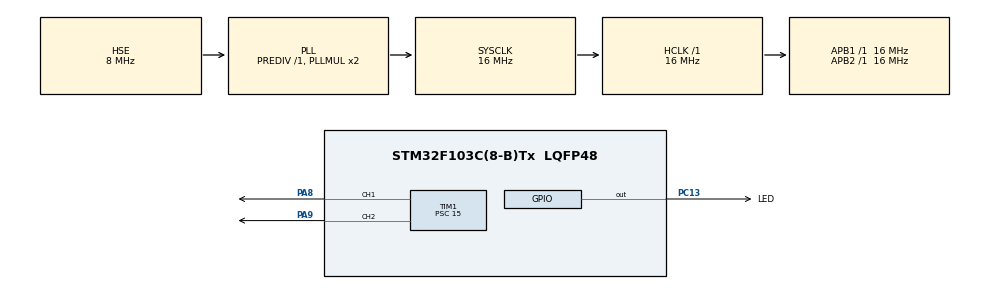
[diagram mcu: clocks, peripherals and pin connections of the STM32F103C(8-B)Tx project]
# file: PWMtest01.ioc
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Mcu.Family=STM32F1
Mcu.Name=STM32F103C(8-B)Tx
Mcu.Package=LQFP48
NVIC.PriorityGroup=NVIC_PRIORITYGROUP_4
PA13.Mode=JTAG_4_pins
PA13.Signal=SYS_JTMS-SWDIO
PA14.Mode=JTAG_4_pins
PA14.Signal=SYS_JTCK-SWCLK
PA15.Mode=JTAG_4_pins
PA15.Signal=SYS_JTDI
PA8.Signal=S_TIM1_CH1
PA9.Signal=S_TIM1_CH2
PB3.Mode=JTAG_4_pins
PB3.Signal=SYS_JTDO-TRACESWO
PC13-TAMPER-RTC.GPIO_Label=LED
PC13-TAMPER-RTC.PinState=GPIO_PIN_SET
PC13-TAMPER-RTC.Signal=GPIO_Output
PD0-OSC_IN.Mode=HSE-External-Oscillator
PD0-OSC_IN.Signal=RCC_OSC_IN
PD1-OSC_OUT.Mode=HSE-External-Oscillator
PD1-OSC_OUT.Signal=RCC_OSC_OUT
ProjectManager.HeapSize=0x200
ProjectManager.StackSize=0x400
ProjectManager.TargetToolchain=MDK-ARM V5.27
RCC.AHBFreq_Value=16000000
RCC.APB1Freq_Value=16000000
RCC.APB1TimFreq_Value=16000000
RCC.APB2Freq_Value=16000000
RCC.APB2TimFreq_Value=16000000
RCC.HCLKFreq_Value=16000000
RCC.PLLSourceVirtual=RCC_PLLSOURCE_HSE
RCC.SYSCLKFreq_VALUE=16000000
RCC.SYSCLKSource=RCC_SYSCLKSOURCE_PLLCLK
RCC.USBFreq_Value=16000000
SH.S_TIM1_CH1.0=TIM1_CH1,PWM Generation1 CH1
SH.S_TIM1_CH2.0=TIM1_CH2,PWM Generation2 CH2
TIM1.AutoReloadPreload=TIM_AUTORELOAD_PRELOAD_ENABLE
TIM1.Channel-PWM\ Generation1\ CH1=TIM_CHANNEL_1
TIM1.Channel-PWM\ Generation2\ CH2=TIM_CHANNEL_2
TIM1.OCMode_PWM-PWM\ Generation2\ CH2=TIM_OCMODE_PWM1
TIM1.Period=20000
TIM1.Prescaler=15
TIM1.Pulse-PWM\ Generation1\ CH1=50
TIM1.Pulse-PWM\ Generation2\ CH2=50
VP_TIM1_VS_ClockSourceINT.Mode=Internal
board=custom

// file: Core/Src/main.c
/* USER CODE BEGIN Header */
/**
  ******************************************************************************
  * @file           : main.c
  * @brief          : Main program body
  ******************************************************************************
  * @attention
  *
  * <h2><center>&copy; Copyright (c) 2021 STMicroelectronics.
  * All rights reserved.</center></h2>
  *
  * This software component is licensed by ST under BSD 3-Clause license,
  * the "License"; You may not use this file except in compliance with the
  * License. You may obtain a copy of the License at:
  *                        opensource.org/licenses/BSD-3-Clause
  *
  ******************************************************************************
  */
/* USER CODE END Header */
#include "main.h"
#include "tim.h"
#include "gpio.h"

/* USER CODE BEGIN Includes */
int j=0,k=0;
/* USER CODE END Includes */

void SystemClock_Config(void);

int main(void)
{

  /* MCU Configuration--------------------------------------------------------*/

  /* Reset of all peripherals, Initializes the Flash interface and the Systick. */
  HAL_Init();

  /* Configure the system clock */
  SystemClock_Config();

  /* Initialize all configured peripherals */
  MX_GPIO_Init();
  MX_TIM1_Init();
  /* USER CODE BEGIN 2 */

  HAL_TIM_PWM_Start(&htim1,TIM_CHANNEL_1);
	HAL_TIM_PWM_Start(&htim1,TIM_CHANNEL_2);
  /* USER CODE END 2 */

  /* Infinite loop */
  /* USER CODE BEGIN WHILE */
  while (1)
  {
		HAL_GPIO_TogglePin(LED_GPIO_Port,LED_Pin);
		HAL_Delay(10);
     __HAL_TIM_SetCompare(&htim1, TIM_CHANNEL_1, j);
		     __HAL_TIM_SetCompare(&htim1, TIM_CHANNEL_2, k);
		j+=10;
		k+=10;
		if(j>19900)j=0;
		if(k>19900)k=0;
    /* USER CODE END WHILE */

  }
}

void SystemClock_Config(void)
{
  RCC_OscInitTypeDef RCC_OscInitStruct = {0};
  RCC_ClkInitTypeDef RCC_ClkInitStruct = {0};

  /** Initializes the RCC Oscillators according to the specified parameters
  * in the RCC_OscInitTypeDef structure.
  */
  RCC_OscInitStruct.OscillatorType = RCC_OSCILLATORTYPE_HSE;
  RCC_OscInitStruct.HSEState = RCC_HSE_ON;
  RCC_OscInitStruct.HSEPredivValue = RCC_HSE_PREDIV_DIV1;
  RCC_OscInitStruct.HSIState = RCC_HSI_ON;
  RCC_OscInitStruct.PLL.PLLState = RCC_PLL_ON;
  RCC_OscInitStruct.PLL.PLLSource = RCC_PLLSOURCE_HSE;
  RCC_OscInitStruct.PLL.PLLMUL = RCC_PLL_MUL2;
  if (HAL_RCC_OscConfig(&RCC_OscInitStruct) != HAL_OK)
  {
    Error_Handler();
  }
  /** Initializes the CPU, AHB and APB buses clocks
  */
  RCC_ClkInitStruct.ClockType = RCC_CLOCKTYPE_HCLK|RCC_CLOCKTYPE_SYSCLK
                              |RCC_CLOCKTYPE_PCLK1|RCC_CLOCKTYPE_PCLK2;
  RCC_ClkInitStruct.SYSCLKSource = RCC_SYSCLKSOURCE_PLLCLK;
  RCC_ClkInitStruct.AHBCLKDivider = RCC_SYSCLK_DIV1;
  RCC_ClkInitStruct.APB1CLKDivider = RCC_HCLK_DIV1;
  RCC_ClkInitStruct.APB2CLKDivider = RCC_HCLK_DIV1;

  if (HAL_RCC_ClockConfig(&RCC_ClkInitStruct, FLASH_LATENCY_0) != HAL_OK)
  {
    Error_Handler();
  }
}

void Error_Handler(void)
{
  __disable_irq();
  while (1)
  {
  }
}

/************************ (C) COPYRIGHT STMicroelectronics *****END OF FILE****/
